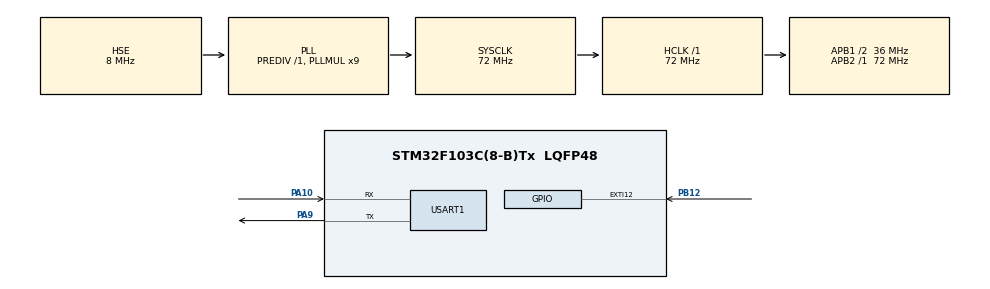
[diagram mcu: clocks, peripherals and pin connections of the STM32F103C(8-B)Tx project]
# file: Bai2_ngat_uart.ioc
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FREERTOS.Queues01=myQueue,16,uint16_t,0,Dynamic,NULL,NULL
FREERTOS.Tasks01=Task_UART,0,128,StartTaskUART,Default,NULL,Dynamic,NULL,NULL
FREERTOS.configTOTAL_HEAP_SIZE=10240
Mcu.Family=STM32F1
Mcu.Name=STM32F103C(8-B)Tx
Mcu.Package=LQFP48
NVIC.EXTI15_10_IRQn=true\:5\:0\:false\:false\:true\:true\:true\:true\:true
NVIC.PriorityGroup=NVIC_PRIORITYGROUP_4
NVIC.TIM4_IRQn=true\:15\:0\:false\:false\:true\:false\:false\:true\:true
NVIC.TimeBase=TIM4_IRQn
NVIC.TimeBaseIP=TIM4
PA10.Mode=Asynchronous
PA10.Signal=USART1_RX
PA13.Mode=Serial_Wire
PA13.Signal=SYS_JTMS-SWDIO
PA14.Mode=Serial_Wire
PA14.Signal=SYS_JTCK-SWCLK
PA9.Mode=Asynchronous
PA9.Signal=USART1_TX
PB12.GPIO_ModeDefaultEXTI=GPIO_MODE_IT_FALLING
PB12.GPIO_PuPd=GPIO_PULLUP
PB12.Signal=GPXTI12
PD0-OSC_IN.Mode=HSE-External-Oscillator
PD0-OSC_IN.Signal=RCC_OSC_IN
PD1-OSC_OUT.Mode=HSE-External-Oscillator
PD1-OSC_OUT.Signal=RCC_OSC_OUT
ProjectManager.HeapSize=0x200
ProjectManager.StackSize=0x400
ProjectManager.TargetToolchain=MDK-ARM V5.32
RCC.AHBFreq_Value=72000000
RCC.APB1CLKDivider=RCC_HCLK_DIV2
RCC.APB1Freq_Value=36000000
RCC.APB1TimFreq_Value=72000000
RCC.APB2Freq_Value=72000000
RCC.APB2TimFreq_Value=72000000
RCC.HCLKFreq_Value=72000000
RCC.PLLMUL=RCC_PLL_MUL9
RCC.PLLSourceVirtual=RCC_PLLSOURCE_HSE
RCC.SYSCLKFreq_VALUE=72000000
RCC.SYSCLKSource=RCC_SYSCLKSOURCE_PLLCLK
RCC.USBFreq_Value=72000000
USART1.VirtualMode=VM_ASYNC
VP_FREERTOS_VS_CMSIS_V1.Mode=CMSIS_V1
VP_SYS_VS_tim4.Mode=TIM4
board=custom

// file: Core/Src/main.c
/* USER CODE BEGIN Header */
/**
  ******************************************************************************
  * @file           : main.c
  * @brief          : Main program body
  ******************************************************************************
  * @attention
  *
  * Copyright (c) 2026 STMicroelectronics.
  * All rights reserved.
  *
  * This software is licensed under terms that can be found in the LICENSE file
  * in the root directory of this software component.
  * If no LICENSE file comes with this software, it is provided AS-IS.
  *
  ******************************************************************************
  */
/* USER CODE END Header */
#include "main.h"
#include "cmsis_os.h"

/* USER CODE BEGIN Includes */
#include <stdio.h>
#include <string.h> //them thu vien string.h de xu ly chuoi
/* USER CODE END Includes */

UART_HandleTypeDef huart1;

osThreadId Task_UARTHandle;
osMessageQId myQueueHandle;

void SystemClock_Config(void);
static void MX_GPIO_Init(void);
static void MX_USART1_UART_Init(void);
void StartTaskUART(void const * argument);

/* USER CODE BEGIN 0 */
  uint16_t button_count = 0; //bien toan cuc dem so lan nhan nut
/* USER CODE END 0 */

int main(void)
{

  /* MCU Configuration--------------------------------------------------------*/

  /* Reset of all peripherals, Initializes the Flash interface and the Systick. */
  HAL_Init();

  /* Configure the system clock */
  SystemClock_Config();

  /* Initialize all configured peripherals */
  MX_GPIO_Init();
  MX_USART1_UART_Init();

  /* Create the queue(s) */
  /* definition and creation of myQueue */
  osMessageQDef(myQueue, 16, uint16_t);
  myQueueHandle = osMessageCreate(osMessageQ(myQueue), NULL);

  /* Create the thread(s) */
  /* definition and creation of Task_UART */
  osThreadDef(Task_UART, StartTaskUART, osPriorityNormal, 0, 128);
  Task_UARTHandle = osThreadCreate(osThread(Task_UART), NULL);

  /* Start scheduler */
  osKernelStart();

  /* We should never get here as control is now taken by the scheduler */

  /* Infinite loop */
  while (1)
  {

  }
}

void SystemClock_Config(void)
{
  RCC_OscInitTypeDef RCC_OscInitStruct = {0};
  RCC_ClkInitTypeDef RCC_ClkInitStruct = {0};

  /** Initializes the RCC Oscillators according to the specified parameters
  * in the RCC_OscInitTypeDef structure.
  */
  RCC_OscInitStruct.OscillatorType = RCC_OSCILLATORTYPE_HSE;
  RCC_OscInitStruct.HSEState = RCC_HSE_ON;
  RCC_OscInitStruct.HSEPredivValue = RCC_HSE_PREDIV_DIV1;
  RCC_OscInitStruct.HSIState = RCC_HSI_ON;
  RCC_OscInitStruct.PLL.PLLState = RCC_PLL_ON;
  RCC_OscInitStruct.PLL.PLLSource = RCC_PLLSOURCE_HSE;
  RCC_OscInitStruct.PLL.PLLMUL = RCC_PLL_MUL9;
  if (HAL_RCC_OscConfig(&RCC_OscInitStruct) != HAL_OK)
  {
    Error_Handler();
  }

  /** Initializes the CPU, AHB and APB buses clocks
  */
  RCC_ClkInitStruct.ClockType = RCC_CLOCKTYPE_HCLK|RCC_CLOCKTYPE_SYSCLK
                              |RCC_CLOCKTYPE_PCLK1|RCC_CLOCKTYPE_PCLK2;
  RCC_ClkInitStruct.SYSCLKSource = RCC_SYSCLKSOURCE_PLLCLK;
  RCC_ClkInitStruct.AHBCLKDivider = RCC_SYSCLK_DIV1;
  RCC_ClkInitStruct.APB1CLKDivider = RCC_HCLK_DIV2;
  RCC_ClkInitStruct.APB2CLKDivider = RCC_HCLK_DIV1;

  if (HAL_RCC_ClockConfig(&RCC_ClkInitStruct, FLASH_LATENCY_2) != HAL_OK)
  {
    Error_Handler();
  }
}

static void MX_USART1_UART_Init(void)
{

  huart1.Instance = USART1;
  huart1.Init.BaudRate = 115200;
  huart1.Init.WordLength = UART_WORDLENGTH_8B;
  huart1.Init.StopBits = UART_STOPBITS_1;
  huart1.Init.Parity = UART_PARITY_NONE;
  huart1.Init.Mode = UART_MODE_TX_RX;
  huart1.Init.HwFlowCtl = UART_HWCONTROL_NONE;
  huart1.Init.OverSampling = UART_OVERSAMPLING_16;
  if (HAL_UART_Init(&huart1) != HAL_OK)
  {
    Error_Handler();
  }

}

static void MX_GPIO_Init(void)
{
  GPIO_InitTypeDef GPIO_InitStruct = {0};

  /* GPIO Ports Clock Enable */
  __HAL_RCC_GPIOD_CLK_ENABLE();
  __HAL_RCC_GPIOB_CLK_ENABLE();
  __HAL_RCC_GPIOA_CLK_ENABLE();

  /*Configure GPIO pin : PB12 */
  GPIO_InitStruct.Pin = GPIO_PIN_12;
  GPIO_InitStruct.Mode = GPIO_MODE_IT_FALLING;
  GPIO_InitStruct.Pull = GPIO_PULLUP;
  HAL_GPIO_Init(GPIOB, &GPIO_InitStruct);

  /* EXTI interrupt init*/
  HAL_NVIC_SetPriority(EXTI15_10_IRQn, 5, 0);
  HAL_NVIC_EnableIRQ(EXTI15_10_IRQn);

}

/* USER CODE BEGIN 4 */ //ham xu ly ngat
void HAL_GPIO_EXTI_Callback(uint16_t GPIO_Pin)
{
  static uint32_t last_time = 0; // Bien luu thoi gian de chong rung

  if(GPIO_Pin == GPIO_PIN_12)
  {
    // Chong rung 200ms
    if(HAL_GetTick() - last_time > 200)
    {
      button_count++; // Tang bien dem
      BaseType_t xHigherPriorityTaskWoken = pdFALSE;

      // Gui du lieu vao Queue (Dung ham rieng cho ISR)
      xQueueSendFromISR((QueueHandle_t)myQueueHandle, &button_count, &xHigherPriorityTaskWoken);

      // Ep Task_UART thuc thi ngay lap tuc
      portYIELD_FROM_ISR(xHigherPriorityTaskWoken);

      last_time = HAL_GetTick(); // Cap nhat thoi gian lan bam cuoi
    }
  }
}
/* USER CODE END 4 */

void StartTaskUART(void const * argument) //ham cho task uart truyen du lieu
{
  /* USER CODE BEGIN 5 */
	char uart_buf[50];
  uint16_t received_count = 0;
	HAL_UART_Transmit(&huart1, (uint8_t*)"UART KHOI DONG OK!\r\n", 20, 100); //test xem da nhan duoc uart hay chua
  /* Infinite loop */
 for(;;)
  {
    // Task ngu cho den khi Queue co tin nhan do Ngat day vao
    if (xQueueReceive((QueueHandle_t)myQueueHandle, &received_count, portMAX_DELAY) == pdPASS)
    {
      // Dong goi chuoi
      sprintf(uart_buf, "So lan nhan nut: %d\r\n", received_count);
      // Truyen len Hercules
      HAL_UART_Transmit(&huart1, (uint8_t*)uart_buf, strlen(uart_buf), 100);
    }
  /* USER CODE END 5 */
}
	}

void HAL_TIM_PeriodElapsedCallback(TIM_HandleTypeDef *htim)
{
  if (htim->Instance == TIM4)
  {
    HAL_IncTick();
  }
}

void Error_Handler(void)
{
  __disable_irq();
  while (1)
  {
  }
}
